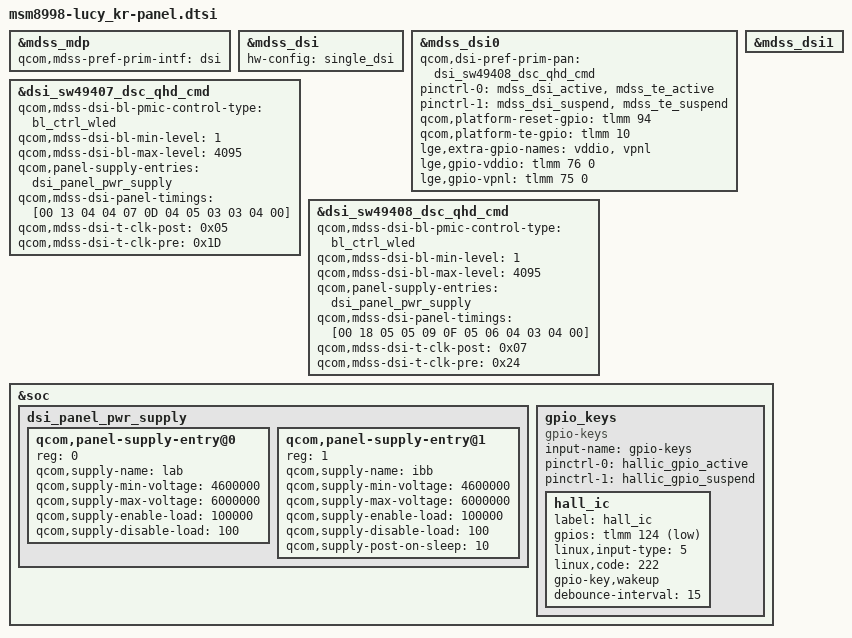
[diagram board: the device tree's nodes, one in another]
/* Copyright (c) 2016, The Linux Foundation. All rights reserved.
 *
 * This program is free software; you can redistribute it and/or modify
 * it under the terms of the GNU General Public License version 2 and
 * only version 2 as published by the Free Software Foundation.
 *
 * This program is distributed in the hope that it will be useful,
 * but WITHOUT ANY WARRANTY; without even the implied warranty of
 * MERCHANTABILITY or FITNESS FOR A PARTICULAR PURPOSE.  See the
 * GNU General Public License for more details.
 */

#include "../../dsi-panel-sw49407-dsc-qhd-cmd.dtsi"
#include "../../dsi-panel-sw49408-dsc-qhd-cmd.dtsi"

&mdss_mdp {
	qcom,mdss-pref-prim-intf = "dsi";
};

&mdss_dsi {
        hw-config = "single_dsi";
};

&mdss_dsi0 {
        qcom,dsi-pref-prim-pan = <&dsi_sw49408_dsc_qhd_cmd>;
        pinctrl-names = "mdss_default", "mdss_sleep";
        pinctrl-0 = <&mdss_dsi_active &mdss_te_active>;
        pinctrl-1 = <&mdss_dsi_suspend &mdss_te_suspend>;
        qcom,platform-reset-gpio = <&tlmm 94 0>;
        qcom,platform-te-gpio = <&tlmm 10 0>;

        lge,extra-gpio-names = "vddio", "vpnl";
        lge,gpio-vddio = <&tlmm 76 0>;
        lge,gpio-vpnl = <&tlmm 75 0>;

        /delete-property/wqhd-vddio-supply;
};

&mdss_dsi1 {
	/delete-property/cell-index;
};

&dsi_sw49407_dsc_qhd_cmd {
        qcom,mdss-dsi-bl-pmic-control-type = "bl_ctrl_wled";
        qcom,mdss-dsi-bl-min-level = <1>;
        qcom,mdss-dsi-bl-max-level = <4095>;
        qcom,panel-supply-entries = <&dsi_panel_pwr_supply>;

	qcom,mdss-dsi-panel-timings = [00 13 04 04 07 0D 04 05 03 03 04 00];
	qcom,mdss-dsi-t-clk-post = <0x05>;
	qcom,mdss-dsi-t-clk-pre = <0x1D>;
};

&dsi_sw49408_dsc_qhd_cmd {
        qcom,mdss-dsi-bl-pmic-control-type = "bl_ctrl_wled";
        qcom,mdss-dsi-bl-min-level = <1>;
        qcom,mdss-dsi-bl-max-level = <4095>;
        qcom,panel-supply-entries = <&dsi_panel_pwr_supply>;

	qcom,mdss-dsi-panel-timings = [00 18 05 05 09 0F 05 06 04 03 04 00];
	qcom,mdss-dsi-t-clk-post = <0x07>;
	qcom,mdss-dsi-t-clk-pre = <0x24>;
};

&soc {
	dsi_panel_pwr_supply: dsi_panel_pwr_supply {
		#address-cells = <1>;
		#size-cells = <0>;
		/delete-node/qcom,panel-supply-entry@2;

		qcom,panel-supply-entry@0 {
			reg = <0>;
			qcom,supply-name = "lab";
			qcom,supply-min-voltage = <4600000>;
			qcom,supply-max-voltage = <6000000>;
			qcom,supply-enable-load = <100000>;
			qcom,supply-disable-load = <100>;
		};

		qcom,panel-supply-entry@1 {
			reg = <1>;
			qcom,supply-name = "ibb";
			qcom,supply-min-voltage = <4600000>;
			qcom,supply-max-voltage = <6000000>;
			qcom,supply-enable-load = <100000>;
			qcom,supply-disable-load = <100>;
			qcom,supply-post-on-sleep = <10>;
		};
	};
};

/* End of overriding parameters in msm8998-mdss-panel.dtsi */

/* Hall IC */
&soc {
        gpio_keys {
                compatible = "gpio-keys";
                input-name = "gpio-keys";

                pinctrl-names = "tlmm_gpio_key_active","tlmm_gpio_key_suspend";
                pinctrl-0 = <&hallic_gpio_active>;
                pinctrl-1 = <&hallic_gpio_suspend>;

                hall_ic {
                        label = "hall_ic";
                        gpios = <&tlmm 124 0x1>;
                        linux,input-type = <5>;
                        linux,code = <222>;
                        gpio-key,wakeup;
                        debounce-interval = <15>;
                };
        };
};
